AUTOSAR XML (schema 00044)
package /E40_Platform_System_SystemPackage/Components
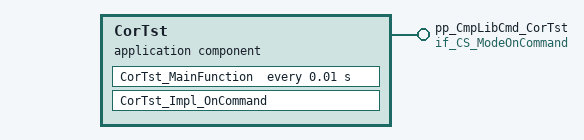
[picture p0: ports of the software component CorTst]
  application sw component type CorTst
    provide port pp_CmpLibCmd_CorTst: server-com-spec{operation=Impl_OnCommand, queue-length=1}, provided-interface=if_CS_ModeOnCommand
    behavior IB_CorTst: port-api-option{enable-take-address=false, indirect-api=false, port=pp_CmpLibCmd_CorTst}
      operation invoked event OIE_pp_CmpLibCmd_CorTst_CorTst_Impl_OnCommandTrigByImpl_OnCommand: start-on-event=CorTst_Impl_OnCommand, operation=pp_CmpLibCmd_CorTst.Impl_OnCommand
      timing event TECorTst_MainFunction: start-on-event=CorTst_MainFunction, period=0.01
      runnable CorTst_Impl_OnCommand: can-be-invoked-concurrently=true
      runnable CorTst_MainFunction: can-be-invoked-concurrently=true
  swc implementation IMPL_CorTst: behavior=IB_CorTst
